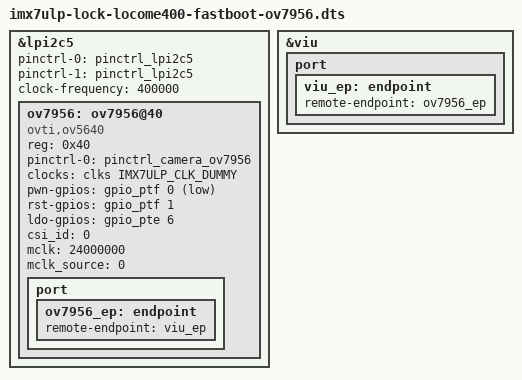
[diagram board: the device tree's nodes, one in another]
/*
 * Copyright 2016 Freescale Semiconductor, Inc.
 * Copyright 2017 NXP.
 *
 * This program is free software; you can redistribute it and/or modify
 * it under the terms of the GNU General Public License version 2 as
 * published by the Free Software Foundation.
 */


#include "imx7ulp-lock-locome400.dts"

&lpi2c5 {
	#address-cells = <1>;
	#size-cells = <0>;
	pinctrl-names = "default", "sleep";
	pinctrl-0 = <&pinctrl_lpi2c5>;
	pinctrl-1 = <&pinctrl_lpi2c5>;
	clock-frequency = <400000>;
	status = "okay";

	ov7956: ov7956@40 {
		compatible = "ovti,ov5640";
		reg = <0x40>;
		pinctrl-names = "default";
		pinctrl-0 = <&pinctrl_camera_ov7956>;
		clocks = <&clks IMX7ULP_CLK_DUMMY>;
		clock-names = "csi_mclk";
		pwn-gpios = <&gpio_ptf 0 GPIO_ACTIVE_LOW>;
		rst-gpios = <&gpio_ptf 1 GPIO_ACTIVE_HIGH>; //change for EC board
		ldo-gpios = <&gpio_pte 6 GPIO_ACTIVE_HIGH>; //add for EC board
		csi_id = <0>;
		mclk = <24000000>;
		mclk_source = <0>;
		status = "okay";

		port {
			ov7956_ep: endpoint {
				remote-endpoint = <&viu_ep>;
			};
		};
	};
};

&viu {
	status = "okay";

	port {
		viu_ep: endpoint {
			remote-endpoint = <&ov7956_ep>;
		};
	};
};

